VERSION ""

NS_ :

BS_:

BU_:

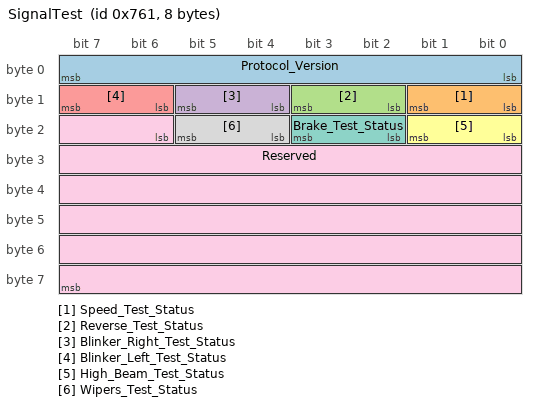
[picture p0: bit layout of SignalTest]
BO_ 1889 SignalTest: 8 Vector__XXX
 SG_ Protocol_Version : 0|8@1+ (1,0) [0|255] "" Vector__XXX
 SG_ Speed_Test_Status : 8|2@1+ (1,0) [0|3] "" Vector__XXX
 SG_ Reverse_Test_Status : 10|2@1+ (1,0) [0|3] "" Vector__XXX
 SG_ Blinker_Right_Test_Status : 12|2@1+ (1,0) [0|3] "" Vector__XXX
 SG_ Blinker_Left_Test_Status : 14|2@1+ (1,0) [0|3] "" Vector__XXX
 SG_ High_Beam_Test_Status : 16|2@1+ (1,0) [0|3] "" Vector__XXX
 SG_ Brake_Test_Status : 18|2@1+ (1,0) [0|3] "" Vector__XXX
 SG_ Wipers_Test_Status : 20|2@1+ (1,0) [0|3] "" Vector__XXX
 SG_ Reserved : 22|42@1+ (1,0) [0|0] "" Vector__XXX

CM_ SG_ 1889 Protocol_Version "Protocol Version";
CM_ SG_ 1889 Speed_Test_Status "Speed signal test status
";
CM_ SG_ 1889 Reverse_Test_Status "Reverse signal test status";
CM_ SG_ 1889 Blinker_Right_Test_Status "Blinker right signal test status";
CM_ SG_ 1889 Blinker_Left_Test_Status "Blinker left signal test status";
CM_ SG_ 1889 High_Beam_Test_Status "High beam signal test status";
CM_ SG_ 1889 Brake_Test_Status "Brake signal test status";
CM_ SG_ 1889 Wipers_Test_Status "Wipers signal test status";
VAL_ 1889 Speed_Test_Status 0 "NOT_TESTED" 1 "IN_TEST" 2 "PASS" 3 "FAIL" ;
VAL_ 1889 Reverse_Test_Status 0 "NOT_TESTED" 1 "IN_TEST" 2 "PASS" 3 "FAIL" ;
VAL_ 1889 Blinker_Right_Test_Status 0 "NOT_TESTED" 1 "IN_TEST" 2 "PASS" 3 "FAIL" ;
VAL_ 1889 Blinker_Left_Test_Status 0 "NOT_TESTED" 1 "IN_TEST" 2 "PASS" 3 "FAIL" ;
VAL_ 1889 High_Beam_Test_Status 0 "NOT_TESTED" 1 "IN_TEST" 2 "PASS" 3 "FAIL" ;
VAL_ 1889 Brake_Test_Status 0 "NOT_TESTED" 1 "IN_TEST" 2 "PASS" 3 "FAIL" ;
VAL_ 1889 Wipers_Test_Status 0 "NOT_TESTED" 1 "IN_TEST" 2 "PASS" 3 "FAIL" ;
